VERSION ""

NS_ :

BS_:

BU_: ECU_NODE

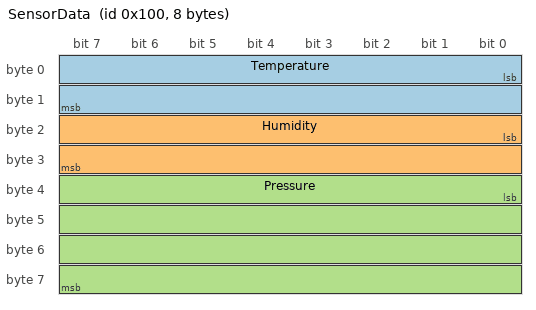
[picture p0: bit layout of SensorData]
BO_ 256 SensorData: 8 ECU_NODE
 SG_ Temperature : 0|16@1+ (0.01,-40) [0|85] "degC" Vector__XXX
 SG_ Humidity : 16|16@1+ (0.01,0) [0|100] "%RH" Vector__XXX
 SG_ Pressure : 32|32@1+ (1,0) [30000|110000] "Pa" Vector__XXX

BO_ 257 ActuatorState: 2 ECU_NODE
 SG_ FanState : 0|8@1+ (1,0) [0|1] "" Vector__XXX
 SG_ Reserved : 8|8@1+ (1,0) [0|0] "" Vector__XXX

BO_ 16 Heartbeat: 4 ECU_NODE
 SG_ UptimeSeconds : 0|32@1+ (1,0) [0|4294967295] "s" Vector__XXX
